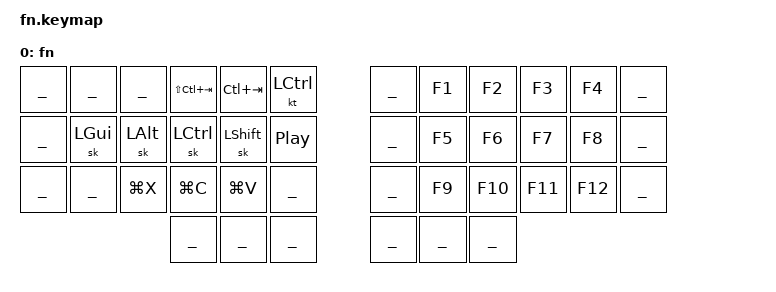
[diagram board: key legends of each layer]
ZMK_LAYER(fn,   // 2
//╭─────────────┬─────────────┬─────────────┬─────────────┬─────────────┬─────────────╮ ╭─────────────┬─────────────┬─────────────┬─────────────┬─────────────┬─────────────╮
    ___           ___           ___         &kp LS(LC(TAB)) &kp LC(TAB)   &kt LCTRL       ___           &kp F1        &kp F2        &kp F3        &kp F4        ___
//├─────────────┼─────────────┼─────────────┼─────────────┼─────────────┼─────────────┤ ├─────────────┼─────────────┼─────────────┼─────────────┼─────────────┴─────────────┤
    ___           &sk LGUI      &sk LALT      &sk LCTRL     &sk LSHFT     &kp C_PP        ___           &kp F5        &kp F6        &kp F7        &kp F8        ___
//├─────────────┼─────────────┼─────────────┼─────────────┼─────────────┼─────────────┤ ├─────────────┼─────────────┼─────────────┼─────────────┼─────────────┴─────────────┤
    ___           ___           &kp LG(X)     &kp LG(C)     &kp LG(V)     ___             ___           &kp F9       &kp F10       &kp F11       &kp F12        ___
//╰─────────────┴─────────────┴─────────────┼─────────────┼─────────────┼─────────────┤ ├─────────────┼─────────────┼─────────────┼─────────────┴─────────────┴─────────────╯
                                              ___           ___           ___             ___           ___           ___ 
//                                          ╰─────────────┴─────────────┴─────────────╯ ╰─────────────┴─────────────┴─────────────╯
)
